# AT91SAM9CN12 register map
Vendor: Atmel; Series: SAM9CN; File version: 20130208
Registers are 32-bit, read-only, reset 0x0 unless marked. A register's access mark holds for its fields unless they carry their own. Offsets are from the block's base; [hi:lo] are bit positions; {n}, {i} and the like mark numbered series; 'fields as' and 'values as' point back to an identical list.

## USART0 — Universal Synchronous Asynchronous Receiver Transmitter 0
Base 0xF801C000; register names take the prefix USART0_
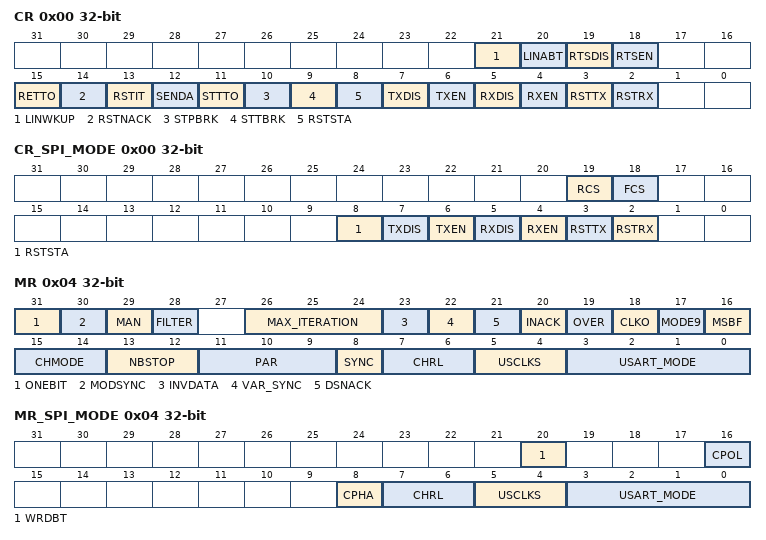
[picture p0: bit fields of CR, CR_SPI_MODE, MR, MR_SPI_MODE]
0x00 CR wo reset not defined — Control Register
  [21] LINWKUP — Send LIN Wakeup Signal
  [20] LINABT — Abort LIN Transmission
  [19] RTSDIS — Request to Send Disable
  [18] RTSEN — Request to Send Enable
  [15] RETTO — Rearm Time-out
  [14] RSTNACK — Reset Non Acknowledge
  [13] RSTIT — Reset Iterations
  [12] SENDA — Send Address
  [11] STTTO — Start Time-out
  [10] STPBRK — Stop Break
  [9] STTBRK — Start Break
  [8] RSTSTA — Reset Status Bits
  [7] TXDIS — Transmitter Disable
  [6] TXEN — Transmitter Enable
  [5] RXDIS — Receiver Disable
  [4] RXEN — Receiver Enable
  [3] RSTTX — Reset Transmitter
  [2] RSTRX — Reset Receiver
0x00 CR_SPI_MODE wo reset not defined (SPI_MODE view) — Control Register
  [19] RCS — Release SPI Chip Select
  [18] FCS — Force SPI Chip Select
  [8] RSTSTA — Reset Status Bits
  [7] TXDIS — Transmitter Disable
  [6] TXEN — Transmitter Enable
  [5] RXDIS — Receiver Disable
  [4] RXEN — Receiver Enable
  [3] RSTTX — Reset Transmitter
  [2] RSTRX — Reset Receiver
0x04 MR rw reset not defined — Mode Register
  [31] ONEBIT — Start Frame Delimiter Selector
  [30] MODSYNC — Manchester Synchronization Mode
  [29] MAN — Manchester Encoder/Decoder Enable
  [28] FILTER — Infrared Receive Line Filter
  [26:24] MAX_ITERATION — Maximum Number of Automatic Iteration
  [23] INVDATA — INverted Data
  [22] VAR_SYNC — Variable Synchronization of Command/Data Sync Start Frame Delimiter
  [21] DSNACK — Disable Successive NACK
  [20] INACK — Inhibit Non Acknowledge
  [19] OVER — Oversampling Mode
  [18] CLKO — Clock Output Select
  [17] MODE9 — 9-bit Character Length
  [16] MSBF — Bit Order
  [15:14] CHMODE — Channel Mode
    0=NORMAL (Normal Mode); 1=AUTOMATIC (Automatic Echo. Receiver input is connected to the TXD pin.); 2=LOCAL_LOOPBACK (Local Loopback. Transmitter output is connected to the Receiver Input.); 3=REMOTE_LOOPBACK (Remote Loopback. RXD pin is internally connected to the TXD pin.)
  [13:12] NBSTOP — Number of Stop Bits
    0=1_BIT (1 stop bit); 1=1_5_BIT (1.5 stop bit (SYNC = 0) or reserved (SYNC = 1)); 2=2_BIT (2 stop bits)
  [11:9] PAR — Parity Type
    0=EVEN (Even parity); 1=ODD (Odd parity); 2=SPACE (Parity forced to 0 (Space)); 3=MARK (Parity forced to 1 (Mark)); 4=NO (No parity); 6=MULTIDROP (Multidrop mode)
  [8] SYNC — Synchronous Mode Select
  [7:6] CHRL — Character Length.
    {v}={v+5}_BIT (Character length is {v+5} bits) (v=0..3)
  [5:4] USCLKS — Clock Selection
    0=MCK (Master Clock MCK is selected); 1=DIV (Internal Clock Divided MCK/DIV (DIV=8) is selected); 3=SCK (Serial Clock SLK is selected)
  [3:0] USART_MODE — USART Mode of Operation
    0=NORMAL (Normal mode); 1=RS485; 2=HW_HANDSHAKING (Hardware Handshaking); 4=IS07816_T_0 (IS07816 Protocol: T = 0); 6=IS07816_T_1 (IS07816 Protocol: T = 1); 8=IRDA; 10=LIN_MASTER; 11=LIN_SLAVE; 14=SPI_MASTER; 15=SPI_SLAVE
0x04 MR_SPI_MODE rw reset not defined (SPI_MODE view) — Mode Register
  [20] WRDBT — Wait Read Data Before Transfer
  [16] CPOL — SPI Clock Polarity
  [8] CPHA — SPI Clock Phase
  [7:6] CHRL — Character Length.
    3=8_BIT (Character length is 8 bits)
  [5:4] USCLKS — Clock Selection
    values as MR.USCLKS
  [3:0] USART_MODE — USART Mode of Operation
    14=SPI_MASTER; 15=SPI_SLAVE
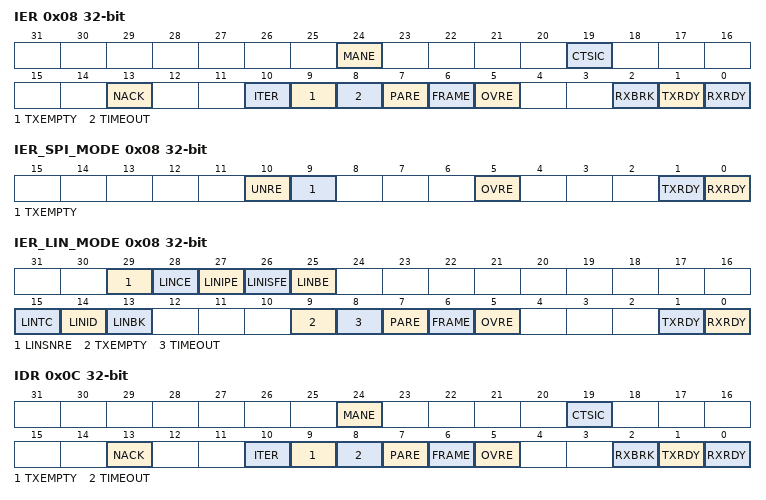
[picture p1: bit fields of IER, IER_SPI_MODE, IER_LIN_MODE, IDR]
0x08 IER wo reset not defined — Interrupt Enable Register
  [24] MANE — Manchester Error Interrupt Enable
  [19] CTSIC — Clear to Send Input Change Interrupt Enable
  [13] NACK — Non Acknowledge Interrupt Enable
  [10] ITER — Max number of Repetitions Reached Interrupt Enable
  [9] TXEMPTY — TXEMPTY Interrupt Enable
  [8] TIMEOUT — Time-out Interrupt Enable
  [7] PARE — Parity Error Interrupt Enable
  [6] FRAME — Framing Error Interrupt Enable
  [5] OVRE — Overrun Error Interrupt Enable
  [2] RXBRK — Receiver Break Interrupt Enable
  [1] TXRDY — TXRDY Interrupt Enable
  [0] RXRDY — RXRDY Interrupt Enable
0x08 IER_SPI_MODE wo reset not defined (SPI_MODE view) — Interrupt Enable Register
  [10] UNRE — SPI Underrun Error Interrupt Enable
  [9] TXEMPTY — TXEMPTY Interrupt Enable
  [5] OVRE — Overrun Error Interrupt Enable
  [1] TXRDY — TXRDY Interrupt Enable
  [0] RXRDY — RXRDY Interrupt Enable
0x08 IER_LIN_MODE wo reset not defined (LIN_MODE view) — Interrupt Enable Register
  [29] LINSNRE — LIN Slave Not Responding Error Interrupt Enable
  [28] LINCE — LIN Checksum Error Interrupt Enable
  [27] LINIPE — LIN Identifier Parity Interrupt Enable
  [26] LINISFE — LIN Inconsistent Synch Field Error Interrupt Enable
  [25] LINBE — LIN Bus Error Interrupt Enable
  [15] LINTC — LIN Transfer Completed Interrupt Enable
  [14] LINID — LIN Identifier Sent or LIN Identifier Received Interrupt Enable
  [13] LINBK — LIN Break Sent or LIN Break Received Interrupt Enable
  [9] TXEMPTY — TXEMPTY Interrupt Enable
  [8] TIMEOUT — Time-out Interrupt Enable
  [7] PARE — Parity Error Interrupt Enable
  [6] FRAME — Framing Error Interrupt Enable
  [5] OVRE — Overrun Error Interrupt Enable
  [1] TXRDY — TXRDY Interrupt Enable
  [0] RXRDY — RXRDY Interrupt Enable
0x0C IDR wo reset not defined — Interrupt Disable Register
  [24] MANE — Manchester Error Interrupt Disable
  [19] CTSIC — Clear to Send Input Change Interrupt Disable
  [13] NACK — Non Acknowledge Interrupt Disable
  [10] ITER — Max number of Repetitions Reached Interrupt Disable
  [9] TXEMPTY — TXEMPTY Interrupt Disable
  [8] TIMEOUT — Time-out Interrupt Disable
  [7] PARE — Parity Error Interrupt Disable
  [6] FRAME — Framing Error Interrupt Disable
  [5] OVRE — Overrun Error Interrupt Enable
  [2] RXBRK — Receiver Break Interrupt Disable
  [1] TXRDY — TXRDY Interrupt Disable
  [0] RXRDY — RXRDY Interrupt Disable
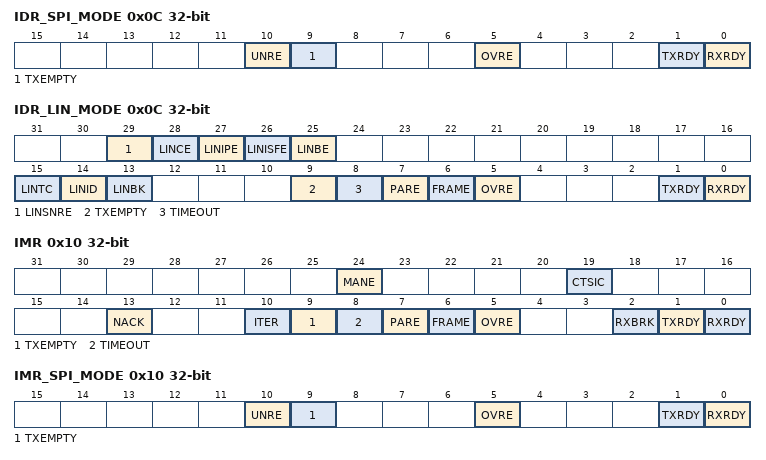
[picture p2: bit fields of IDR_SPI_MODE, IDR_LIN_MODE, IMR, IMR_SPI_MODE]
0x0C IDR_SPI_MODE wo reset not defined (SPI_MODE view) — Interrupt Disable Register
  [10] UNRE — SPI Underrun Error Interrupt Disable
  [9] TXEMPTY — TXEMPTY Interrupt Disable
  [5] OVRE — Overrun Error Interrupt Disable
  [1] TXRDY — TXRDY Interrupt Disable
  [0] RXRDY — RXRDY Interrupt Disable
0x0C IDR_LIN_MODE wo reset not defined (LIN_MODE view) — Interrupt Disable Register
  [29] LINSNRE — LIN Slave Not Responding Error Interrupt Disable
  [28] LINCE — LIN Checksum Error Interrupt Disable
  [27] LINIPE — LIN Identifier Parity Interrupt Disable
  [26] LINISFE — LIN Inconsistent Synch Field Error Interrupt Disable
  [25] LINBE — LIN Bus Error Interrupt Disable
  [15] LINTC — LIN Transfer Completed Interrupt Disable
  [14] LINID — LIN Identifier Sent or LIN Identifier Received Interrupt Disable
  [13] LINBK — LIN Break Sent or LIN Break Received Interrupt Disable
  [9] TXEMPTY — TXEMPTY Interrupt Disable
  [8] TIMEOUT — Time-out Interrupt Disable
  [7] PARE — Parity Error Interrupt Disable
  [6] FRAME — Framing Error Interrupt Disable
  [5] OVRE — Overrun Error Interrupt Disable
  [1] TXRDY — TXRDY Interrupt Disable
  [0] RXRDY — RXRDY Interrupt Disable
0x10 IMR — Interrupt Mask Register
  [24] MANE — Manchester Error Interrupt Mask
  [19] CTSIC — Clear to Send Input Change Interrupt Mask
  [13] NACK — Non Acknowledge Interrupt Mask
  [10] ITER — Max number of Repetitions Reached Interrupt Mask
  [9] TXEMPTY — TXEMPTY Interrupt Mask
  [8] TIMEOUT — Time-out Interrupt Mask
  [7] PARE — Parity Error Interrupt Mask
  [6] FRAME — Framing Error Interrupt Mask
  [5] OVRE — Overrun Error Interrupt Mask
  [2] RXBRK — Receiver Break Interrupt Mask
  [1] TXRDY — TXRDY Interrupt Mask
  [0] RXRDY — RXRDY Interrupt Mask
0x10 IMR_SPI_MODE (SPI_MODE view) — Interrupt Mask Register
  [10] UNRE — SPI Underrun Error Interrupt Mask
  [9] TXEMPTY — TXEMPTY Interrupt Mask
  [5] OVRE — Overrun Error Interrupt Mask
  [1] TXRDY — TXRDY Interrupt Mask
  [0] RXRDY — RXRDY Interrupt Mask
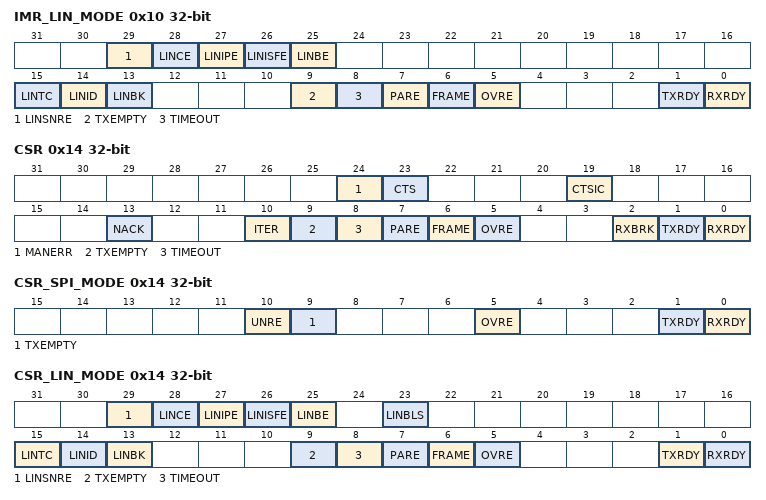
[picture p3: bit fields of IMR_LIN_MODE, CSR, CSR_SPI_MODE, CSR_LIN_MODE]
0x10 IMR_LIN_MODE (LIN_MODE view) — Interrupt Mask Register
  [29] LINSNRE — LIN Slave Not Responding Error Interrupt Mask
  [28] LINCE — LIN Checksum Error Interrupt Mask
  [27] LINIPE — LIN Identifier Parity Interrupt Mask
  [26] LINISFE — LIN Inconsistent Synch Field Error Interrupt Mask
  [25] LINBE — LIN Bus Error Interrupt Mask
  [15] LINTC — LIN Transfer Completed Interrupt Mask
  [14] LINID — LIN Identifier Sent or LIN Identifier Received Interrupt Mask
  [13] LINBK — LIN Break Sent or LIN Break Received Interrupt Mask
  [9] TXEMPTY — TXEMPTY Interrupt Mask
  [8] TIMEOUT — Time-out Interrupt Mask
  [7] PARE — Parity Error Interrupt Mask
  [6] FRAME — Framing Error Interrupt Mask
  [5] OVRE — Overrun Error Interrupt Mask
  [1] TXRDY — TXRDY Interrupt Mask
  [0] RXRDY — RXRDY Interrupt Mask
0x14 CSR reset not defined — Channel Status Register
  [24] MANERR — Manchester Error
  [23] CTS — Image of CTS Input
  [19] CTSIC — Clear to Send Input Change Flag
  [13] NACK — Non Acknowledge Interrupt
  [10] ITER — Max number of Repetitions Reached
  [9] TXEMPTY — Transmitter Empty
  [8] TIMEOUT — Receiver Time-out
  [7] PARE — Parity Error
  [6] FRAME — Framing Error
  [5] OVRE — Overrun Error
  [2] RXBRK — Break Received/End of Break
  [1] TXRDY — Transmitter Ready
  [0] RXRDY — Receiver Ready
0x14 CSR_SPI_MODE reset not defined (SPI_MODE view) — Channel Status Register
  [10] UNRE — Underrun Error
  [9] TXEMPTY — Transmitter Empty
  [5] OVRE — Overrun Error
  [1] TXRDY — Transmitter Ready
  [0] RXRDY — Receiver Ready
0x14 CSR_LIN_MODE reset not defined (LIN_MODE view) — Channel Status Register
  [29] LINSNRE — LIN Slave Not Responding Error
  [28] LINCE — LIN Checksum Error
  [27] LINIPE — LIN Identifier Parity Error
  [26] LINISFE — LIN Inconsistent Synch Field Error
  [25] LINBE — LIN Bit Error
  [23] LINBLS — LIN Bus Line Status
  [15] LINTC — LIN Transfer Completed
  [14] LINID — LIN Identifier Sent or LIN Identifier Received
  [13] LINBK — LIN Break Sent or LIN Break Received
  [9] TXEMPTY — Transmitter Empty
  [8] TIMEOUT — Receiver Time-out
  [7] PARE — Parity Error
  [6] FRAME — Framing Error
  [5] OVRE — Overrun Error
  [1] TXRDY — Transmitter Ready
  [0] RXRDY — Receiver Ready
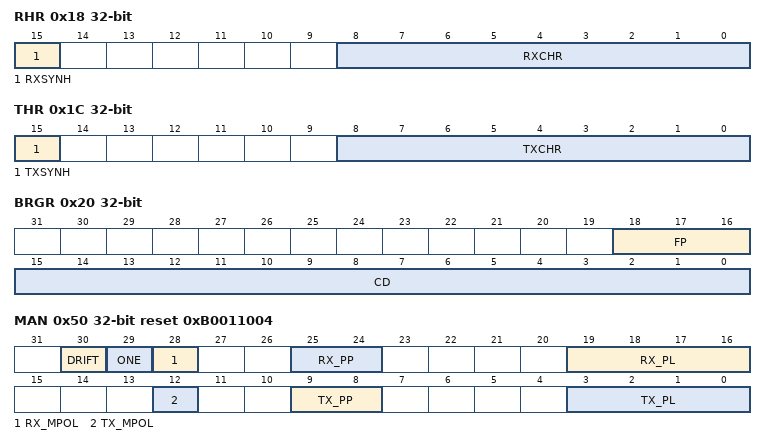
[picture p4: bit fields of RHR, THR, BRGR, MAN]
0x18 RHR — Receiver Holding Register
  [15] RXSYNH — Received Sync
  [8:0] RXCHR — Received Character
0x1C THR wo reset not defined — Transmitter Holding Register
  [15] TXSYNH — Sync Field to be transmitted
  [8:0] TXCHR — Character to be Transmitted
0x20 BRGR rw — Baud Rate Generator Register
  [18:16] FP — Fractional Part
  [15:0] CD — Clock Divider
0x24 RTOR rw — Receiver Time-out Register
  [16:0] TO — Time-out Value
0x28 TTGR rw — Transmitter Timeguard Register
  [7:0] TG — Timeguard Value
0x40 FIDI rw reset 0x174 — FI DI Ratio Register
  [10:0] FI_DI_RATIO — FI Over DI Ratio Value
0x44 NER reset not defined — Number of Errors Register
  [7:0] NB_ERRORS — Number of Errors
0x4C IF rw — IrDA Filter Register
  [7:0] IRDA_FILTER
0x50 MAN rw reset 0xB0011004 — Manchester Encoder Decoder Register
  [30] DRIFT — Drift compensation
  [29] ONE — Must Be Set to 1
  [28] RX_MPOL — Receiver Manchester Polarity
  [25:24] RX_PP — Receiver Preamble Pattern detected
    0=ALL_ONE (The preamble is composed of '1's); 1=ALL_ZERO (The preamble is composed of '0's); 2=ZERO_ONE (The preamble is composed of '01's); 3=ONE_ZERO (The preamble is composed of '10's)
  [19:16] RX_PL — Receiver Preamble Length
  [12] TX_MPOL — Transmitter Manchester Polarity
  [9:8] TX_PP — Transmitter Preamble Pattern
    values as RX_PP
  [3:0] TX_PL — Transmitter Preamble Length
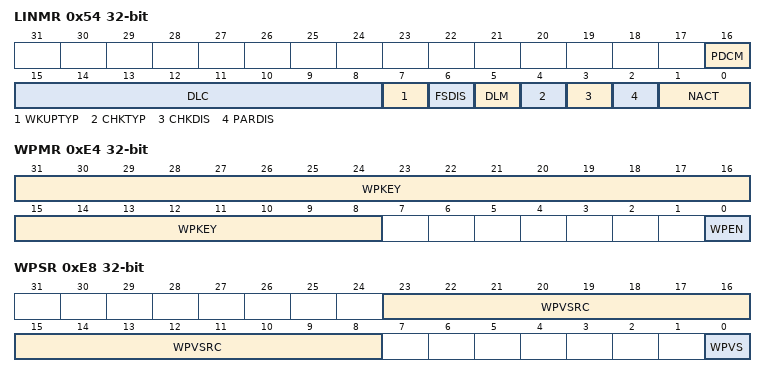
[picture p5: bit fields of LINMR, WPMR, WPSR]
0x54 LINMR rw — LIN Mode Register
  [16] PDCM — DMAC Mode
  [15:8] DLC — Data Length Control
  [7] WKUPTYP — Wakeup Signal Type
  [6] FSDIS — Frame Slot Mode Disable
  [5] DLM — Data Length Mode
  [4] CHKTYP — Checksum Type
  [3] CHKDIS — Checksum Disable
  [2] PARDIS — Parity Disable
  [1:0] NACT — LIN Node Action
    0=PUBLISH (The USART transmits the response.); 1=SUBSCRIBE (The USART receives the response.); 2=IGNORE (The USART does not transmit and does not receive the response.)
0x58 LINIR rw — LIN Identifier Register
  [7:0] IDCHR — Identifier Character
0xE4 WPMR rw — Write Protect Mode Register
  [31:8] WPKEY — Write Protect KEY
  [0] WPEN — Write Protect Enable
0xE8 WPSR — Write Protect Status Register
  [23:8] WPVSRC — Write Protect Violation Source
  [0] WPVS — Write Protect Violation Status

## USART1 — Universal Synchronous Asynchronous Receiver Transmitter 1
Base 0xF8020000; register names take the prefix USART1_
Registers as USART0.

## USART2 — Universal Synchronous Asynchronous Receiver Transmitter 2
Base 0xF8024000; register names take the prefix USART2_
Registers as USART0.

## USART3 — Universal Synchronous Asynchronous Receiver Transmitter 3
Base 0xF8028000; register names take the prefix USART3_
Registers as USART0.
